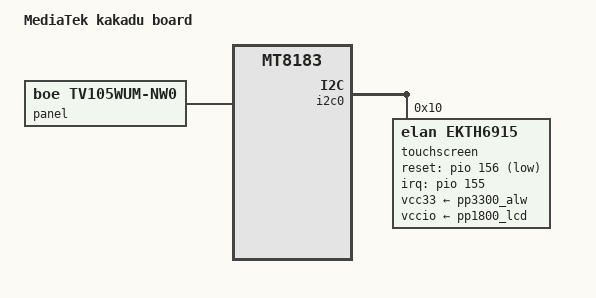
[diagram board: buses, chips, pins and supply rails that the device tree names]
// SPDX-License-Identifier: (GPL-2.0 OR MIT)
/*
 * Copyright 2020 Google LLC
 */

/dts-v1/;
#include "mt8183-kukui-kakadu.dtsi"
#include "mt8183-kukui-audio-da7219-rt1015p.dtsi"

/ {
	model = "MediaTek kakadu board";
	chassis-type = "tablet";
	compatible = "google,kakadu-rev3", "google,kakadu-rev2",
			"google,kakadu", "mediatek,mt8183";
};

&i2c0 {
	touchscreen@10 {
		compatible = "elan,ekth6915";
		reg = <0x10>;
		pinctrl-names = "default";
		pinctrl-0 = <&open_touch>;
		interrupts-extended = <&pio 155 IRQ_TYPE_EDGE_FALLING>;
		reset-gpios = <&pio 156 GPIO_ACTIVE_LOW>;
		vcc33-supply = <&pp3300_alw>;
		vccio-supply = <&pp1800_lcd>;
		no-reset-on-power-off;
	};
};

&panel {
	compatible = "boe,tv105wum-nw0";
};
